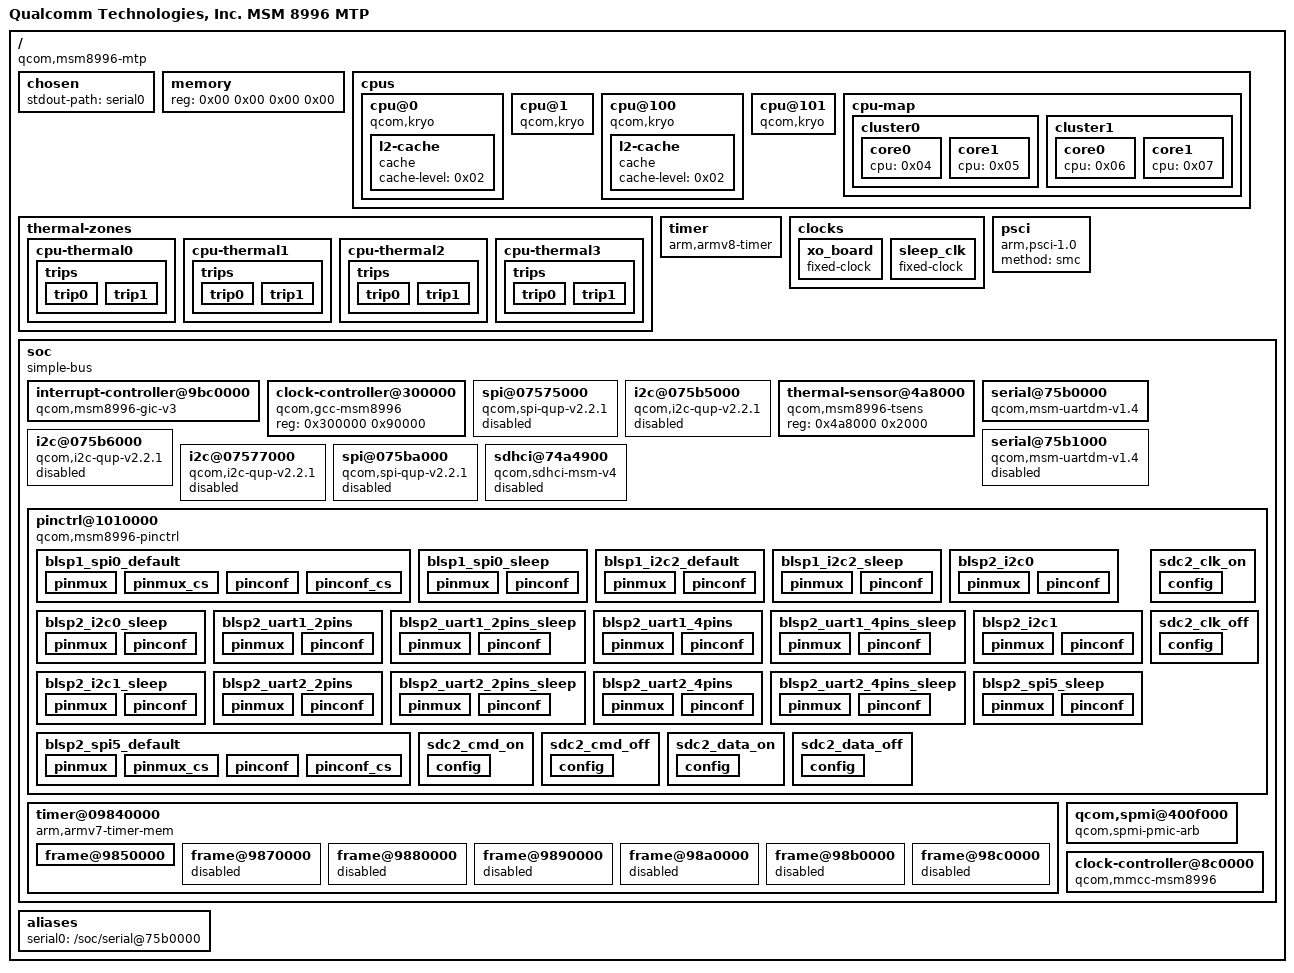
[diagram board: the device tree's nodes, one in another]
/dts-v1/;

/ {
	model = "Qualcomm Technologies, Inc. MSM 8996 MTP";
	interrupt-parent = <0x01>;
	#address-cells = <0x02>;
	#size-cells = <0x02>;
	compatible = "qcom,msm8996-mtp";

	chosen {
		stdout-path = "serial0";
	};

	memory {
		device_type = "memory";
		reg = <0x00 0x00 0x00 0x00>;
	};

	cpus {
		#address-cells = <0x02>;
		#size-cells = <0x00>;

		cpu@0 {
			device_type = "cpu";
			compatible = "qcom,kryo";
			reg = <0x00 0x00>;
			enable-method = "psci";
			next-level-cache = <0x02>;
			phandle = <0x04>;

			l2-cache {
				compatible = "cache";
				cache-level = <0x02>;
				phandle = <0x02>;
			};
		};

		cpu@1 {
			device_type = "cpu";
			compatible = "qcom,kryo";
			reg = <0x00 0x01>;
			enable-method = "psci";
			next-level-cache = <0x02>;
			phandle = <0x05>;
		};

		cpu@100 {
			device_type = "cpu";
			compatible = "qcom,kryo";
			reg = <0x00 0x100>;
			enable-method = "psci";
			next-level-cache = <0x03>;
			phandle = <0x06>;

			l2-cache {
				compatible = "cache";
				cache-level = <0x02>;
				phandle = <0x03>;
			};
		};

		cpu@101 {
			device_type = "cpu";
			compatible = "qcom,kryo";
			reg = <0x00 0x101>;
			enable-method = "psci";
			next-level-cache = <0x03>;
			phandle = <0x07>;
		};

		cpu-map {

			cluster0 {

				core0 {
					cpu = <0x04>;
				};

				core1 {
					cpu = <0x05>;
				};
			};

			cluster1 {

				core0 {
					cpu = <0x06>;
				};

				core1 {
					cpu = <0x07>;
				};
			};
		};
	};

	thermal-zones {

		cpu-thermal0 {
			polling-delay-passive = <0xfa>;
			polling-delay = <0x3e8>;
			thermal-sensors = <0x08 0x03>;

			trips {

				trip0 {
					temperature = <0x124f8>;
					hysteresis = <0x7d0>;
					type = "passive";
					phandle = <0x15>;
				};

				trip1 {
					temperature = <0x1adb0>;
					hysteresis = <0x7d0>;
					type = "critical";
					phandle = <0x16>;
				};
			};
		};

		cpu-thermal1 {
			polling-delay-passive = <0xfa>;
			polling-delay = <0x3e8>;
			thermal-sensors = <0x08 0x05>;

			trips {

				trip0 {
					temperature = <0x124f8>;
					hysteresis = <0x7d0>;
					type = "passive";
					phandle = <0x17>;
				};

				trip1 {
					temperature = <0x1adb0>;
					hysteresis = <0x7d0>;
					type = "critical";
					phandle = <0x18>;
				};
			};
		};

		cpu-thermal2 {
			polling-delay-passive = <0xfa>;
			polling-delay = <0x3e8>;
			thermal-sensors = <0x08 0x08>;

			trips {

				trip0 {
					temperature = <0x124f8>;
					hysteresis = <0x7d0>;
					type = "passive";
					phandle = <0x19>;
				};

				trip1 {
					temperature = <0x1adb0>;
					hysteresis = <0x7d0>;
					type = "critical";
					phandle = <0x1a>;
				};
			};
		};

		cpu-thermal3 {
			polling-delay-passive = <0xfa>;
			polling-delay = <0x3e8>;
			thermal-sensors = <0x08 0x0a>;

			trips {

				trip0 {
					temperature = <0x124f8>;
					hysteresis = <0x7d0>;
					type = "passive";
					phandle = <0x1b>;
				};

				trip1 {
					temperature = <0x1adb0>;
					hysteresis = <0x7d0>;
					type = "critical";
					phandle = <0x1c>;
				};
			};
		};
	};

	timer {
		compatible = "arm,armv8-timer";
		interrupts = <0x01 0x0d 0xf08 0x01 0x0e 0xf08 0x01 0x0b 0xf08 0x01 0x0a 0xf08>;
	};

	clocks {

		xo_board {
			compatible = "fixed-clock";
			#clock-cells = <0x00>;
			clock-frequency = <0x124f800>;
			clock-output-names = "xo_board";
		};

		sleep_clk {
			compatible = "fixed-clock";
			#clock-cells = <0x00>;
			clock-frequency = <0x7ffc>;
			clock-output-names = "sleep_clk";
		};
	};

	psci {
		compatible = "arm,psci-1.0";
		method = "smc";
	};

	soc {
		#address-cells = <0x01>;
		#size-cells = <0x01>;
		ranges = <0x00 0x00 0x00 0xffffffff>;
		compatible = "simple-bus";
		phandle = <0x1d>;

		interrupt-controller@9bc0000 {
			compatible = "qcom,msm8996-gic-v3\0arm,gic-v3";
			#interrupt-cells = <0x03>;
			interrupt-controller;
			#redistributor-regions = <0x01>;
			redistributor-stride = <0x00 0x40000>;
			reg = <0x9bc0000 0x10000 0x9c00000 0x100000>;
			interrupts = <0x01 0x09 0x04>;
			phandle = <0x01>;
		};

		clock-controller@300000 {
			compatible = "qcom,gcc-msm8996";
			#clock-cells = <0x01>;
			#reset-cells = <0x01>;
			#power-domain-cells = <0x01>;
			reg = <0x300000 0x90000>;
			phandle = <0x09>;
		};

		spi@07575000 {
			compatible = "qcom,spi-qup-v2.2.1";
			reg = <0x7575000 0x600>;
			interrupts = <0x00 0x5f 0x04>;
			clocks = <0x09 0x6f 0x09 0x6d>;
			clock-names = "core\0iface";
			pinctrl-names = "default\0sleep";
			pinctrl-0 = <0x0a>;
			pinctrl-1 = <0x0b>;
			#address-cells = <0x01>;
			#size-cells = <0x00>;
			status = "disabled";
			phandle = <0x1e>;
		};

		i2c@075b5000 {
			compatible = "qcom,i2c-qup-v2.2.1";
			reg = <0x75b5000 0x1000>;
			interrupts = <0x00 0x65 0x00>;
			clocks = <0x09 0x81 0x09 0x84>;
			clock-names = "iface\0core";
			pinctrl-names = "default\0sleep";
			pinctrl-0 = <0x0c>;
			pinctrl-1 = <0x0d>;
			#address-cells = <0x01>;
			#size-cells = <0x00>;
			status = "disabled";
			phandle = <0x1f>;
		};

		thermal-sensor@4a8000 {
			compatible = "qcom,msm8996-tsens";
			reg = <0x4a8000 0x2000>;
			#thermal-sensor-cells = <0x01>;
			phandle = <0x08>;
		};

		serial@75b0000 {
			compatible = "qcom,msm-uartdm-v1.4\0qcom,msm-uartdm";
			reg = <0x75b0000 0x1000>;
			interrupts = <0x00 0x72 0x04>;
			clocks = <0x09 0x88 0x09 0x81>;
			clock-names = "core\0iface";
			status = "okay";
			phandle = <0x20>;
		};

		i2c@075b6000 {
			compatible = "qcom,i2c-qup-v2.2.1";
			reg = <0x75b6000 0x1000>;
			interrupts = <0x00 0x66 0x00>;
			clocks = <0x09 0x81 0x09 0x87>;
			clock-names = "iface\0core";
			pinctrl-names = "default\0sleep";
			pinctrl-0 = <0x0e>;
			pinctrl-1 = <0x0f>;
			#address-cells = <0x01>;
			#size-cells = <0x00>;
			status = "disabled";
			phandle = <0x21>;
		};

		serial@75b1000 {
			compatible = "qcom,msm-uartdm-v1.4\0qcom,msm-uartdm";
			reg = <0x75b1000 0x1000>;
			interrupts = <0x00 0x73 0x04>;
			clocks = <0x09 0x8b 0x09 0x81>;
			clock-names = "core\0iface";
			status = "disabled";
			phandle = <0x22>;
		};

		i2c@07577000 {
			compatible = "qcom,i2c-qup-v2.2.1";
			reg = <0x7577000 0x1000>;
			interrupts = <0x00 0x61 0x00>;
			clocks = <0x09 0x6d 0x09 0x76>;
			clock-names = "iface\0core";
			pinctrl-names = "default\0sleep";
			pinctrl-0 = <0x10>;
			pinctrl-1 = <0x11>;
			#address-cells = <0x01>;
			#size-cells = <0x00>;
			status = "disabled";
			phandle = <0x23>;
		};

		spi@075ba000 {
			compatible = "qcom,spi-qup-v2.2.1";
			reg = <0x75ba000 0x600>;
			interrupts = <0x00 0x6a 0x04>;
			clocks = <0x09 0x92 0x09 0x81>;
			clock-names = "core\0iface";
			pinctrl-names = "default\0sleep";
			pinctrl-0 = <0x12>;
			pinctrl-1 = <0x13>;
			#address-cells = <0x01>;
			#size-cells = <0x00>;
			status = "disabled";
			phandle = <0x24>;
		};

		sdhci@74a4900 {
			status = "disabled";
			compatible = "qcom,sdhci-msm-v4";
			reg = <0x74a4900 0x314 0x74a4000 0x800>;
			reg-names = "hc_mem\0core_mem";
			interrupts = <0x00 0x7d 0x00 0x00 0xdd 0x00>;
			interrupt-names = "hc_irq\0pwr_irq";
			clock-names = "iface\0core";
			clocks = <0x09 0x68 0x09 0x67>;
			bus-width = <0x04>;
			phandle = <0x25>;
		};

		pinctrl@1010000 {
			compatible = "qcom,msm8996-pinctrl";
			reg = <0x1010000 0x300000>;
			interrupts = <0x00 0xd0 0x04>;
			gpio-controller;
			#gpio-cells = <0x02>;
			interrupt-controller;
			#interrupt-cells = <0x02>;
			phandle = <0x26>;

			blsp1_spi0_default {
				phandle = <0x0a>;

				pinmux {
					function = "blsp_spi1";
					pins = "gpio0\0gpio1\0gpio3";
				};

				pinmux_cs {
					function = "gpio";
					pins = "gpio2";
				};

				pinconf {
					pins = "gpio0\0gpio1\0gpio3";
					drive-strength = <0x0c>;
					bias-disable;
				};

				pinconf_cs {
					pins = "gpio2";
					drive-strength = <0x10>;
					bias-disable;
					output-high;
				};
			};

			blsp1_spi0_sleep {
				phandle = <0x0b>;

				pinmux {
					function = "gpio";
					pins = "gpio0\0gpio1\0gpio2\0gpio3";
				};

				pinconf {
					pins = "gpio0\0gpio1\0gpio2\0gpio3";
					drive-strength = <0x02>;
					bias-pull-down;
				};
			};

			blsp1_i2c2_default {
				phandle = <0x10>;

				pinmux {
					function = "blsp_i2c3";
					pins = "gpio47\0gpio48";
				};

				pinconf {
					pins = "gpio47\0gpio48";
					drive-strength = <0x10>;
					bias-disable = <0x00>;
				};
			};

			blsp1_i2c2_sleep {
				phandle = <0x11>;

				pinmux {
					function = "gpio";
					pins = "gpio47\0gpio48";
				};

				pinconf {
					pins = "gpio47\0gpio48";
					drive-strength = <0x02>;
					bias-disable = <0x00>;
				};
			};

			blsp2_i2c0 {
				phandle = <0x0c>;

				pinmux {
					function = "blsp_i2c7";
					pins = "gpio55\0gpio56";
				};

				pinconf {
					pins = "gpio55\0gpio56";
					drive-strength = <0x10>;
					bias-disable;
				};
			};

			blsp2_i2c0_sleep {
				phandle = <0x0d>;

				pinmux {
					function = "gpio";
					pins = "gpio55\0gpio56";
				};

				pinconf {
					pins = "gpio55\0gpio56";
					drive-strength = <0x02>;
					bias-disable;
				};
			};

			blsp2_uart1_2pins {
				phandle = <0x27>;

				pinmux {
					function = "blsp_uart8";
					pins = "gpio4\0gpio5";
				};

				pinconf {
					pins = "gpio4\0gpio5";
					drive-strength = <0x10>;
					bias-disable;
				};
			};

			blsp2_uart1_2pins_sleep {
				phandle = <0x28>;

				pinmux {
					function = "gpio";
					pins = "gpio4\0gpio5";
				};

				pinconf {
					pins = "gpio4\0gpio5";
					drive-strength = <0x02>;
					bias-disable;
				};
			};

			blsp2_uart1_4pins {
				phandle = <0x29>;

				pinmux {
					function = "blsp_uart8";
					pins = "gpio4\0gpio5\0gpio6\0gpio7";
				};

				pinconf {
					pins = "gpio4\0gpio5\0gpio6\0gpio7";
					drive-strength = <0x10>;
					bias-disable;
				};
			};

			blsp2_uart1_4pins_sleep {
				phandle = <0x2a>;

				pinmux {
					function = "gpio";
					pins = "gpio4\0gpio5\0gpio6\0gpio7";
				};

				pinconf {
					pins = "gpio4\0gpiio5\0gpio6\0gpio7";
					drive-strength = <0x02>;
					bias-disable;
				};
			};

			blsp2_i2c1 {
				phandle = <0x0e>;

				pinmux {
					function = "blsp_i2c8";
					pins = "gpio6\0gpio7";
				};

				pinconf {
					pins = "gpio6\0gpio7";
					drive-strength = <0x10>;
					bias-disable;
				};
			};

			blsp2_i2c1_sleep {
				phandle = <0x0f>;

				pinmux {
					function = "gpio";
					pins = "gpio6\0gpio7";
				};

				pinconf {
					pins = "gpio6\0gpio7";
					drive-strength = <0x02>;
					bias-disable;
				};
			};

			blsp2_uart2_2pins {
				phandle = <0x2b>;

				pinmux {
					function = "blsp_uart9";
					pins = "gpio49\0gpio50";
				};

				pinconf {
					pins = "gpio49\0gpio50";
					drive-strength = <0x10>;
					bias-disable;
				};
			};

			blsp2_uart2_2pins_sleep {
				phandle = <0x2c>;

				pinmux {
					function = "gpio";
					pins = "gpio49\0gpio50";
				};

				pinconf {
					pins = "gpio49\0gpio50";
					drive-strength = <0x02>;
					bias-disable;
				};
			};

			blsp2_uart2_4pins {
				phandle = <0x2d>;

				pinmux {
					function = "blsp_uart9";
					pins = "gpio49\0gpio50\0gpio51\0gpio52";
				};

				pinconf {
					pins = "gpio49\0gpio50\0gpio51\0gpio52";
					drive-strength = <0x10>;
					bias-disable;
				};
			};

			blsp2_uart2_4pins_sleep {
				phandle = <0x2e>;

				pinmux {
					function = "gpio";
					pins = "gpio49\0gpio50\0gpio51\0gpio52";
				};

				pinconf {
					pins = "gpio49\0gpio50\0gpio51\0gpio52";
					drive-strength = <0x02>;
					bias-disable;
				};
			};

			blsp2_spi5_default {
				phandle = <0x12>;

				pinmux {
					function = "blsp_spi12";
					pins = "gpio85\0gpio86\0gpio88";
				};

				pinmux_cs {
					function = "gpio";
					pins = "gpio87";
				};

				pinconf {
					pins = "gpio85\0gpio86\0gpio88";
					drive-strength = <0x0c>;
					bias-disable;
				};

				pinconf_cs {
					pins = "gpio87";
					drive-strength = <0x10>;
					bias-disable;
					output-high;
				};
			};

			blsp2_spi5_sleep {
				phandle = <0x13>;

				pinmux {
					function = "gpio";
					pins = "gpio85\0gpio86\0gpio87\0gpio88";
				};

				pinconf {
					pins = "gpio85\0gpio86\0gpio87\0gpio88";
					drive-strength = <0x02>;
					bias-pull-down;
				};
			};

			sdc2_clk_on {
				phandle = <0x2f>;

				config {
					pins = "sdc2_clk";
					bias-disable;
					drive-strength = <0x10>;
				};
			};

			sdc2_clk_off {
				phandle = <0x30>;

				config {
					pins = "sdc2_clk";
					bias-disable;
					drive-strength = <0x02>;
				};
			};

			sdc2_cmd_on {
				phandle = <0x31>;

				config {
					pins = "sdc2_cmd";
					bias-pull-up;
					drive-strength = <0x0a>;
				};
			};

			sdc2_cmd_off {
				phandle = <0x32>;

				config {
					pins = "sdc2_cmd";
					bias-pull-up;
					drive-strength = <0x02>;
				};
			};

			sdc2_data_on {
				phandle = <0x33>;

				config {
					pins = "sdc2_data";
					bias-pull-up;
					drive-strength = <0x0a>;
				};
			};

			sdc2_data_off {
				phandle = <0x34>;

				config {
					pins = "sdc2_data";
					bias-pull-up;
					drive-strength = <0x02>;
				};
			};
		};

		timer@09840000 {
			#address-cells = <0x01>;
			#size-cells = <0x01>;
			ranges;
			compatible = "arm,armv7-timer-mem";
			reg = <0x9840000 0x1000>;
			clock-frequency = <0x124f800>;

			frame@9850000 {
				frame-number = <0x00>;
				interrupts = <0x00 0x1f 0x04 0x00 0x1e 0x04>;
				reg = <0x9850000 0x1000 0x9860000 0x1000>;
			};

			frame@9870000 {
				frame-number = <0x01>;
				interrupts = <0x00 0x20 0x04>;
				reg = <0x9870000 0x1000>;
				status = "disabled";
			};

			frame@9880000 {
				frame-number = <0x02>;
				interrupts = <0x00 0x21 0x04>;
				reg = <0x9880000 0x1000>;
				status = "disabled";
			};

			frame@9890000 {
				frame-number = <0x03>;
				interrupts = <0x00 0x22 0x04>;
				reg = <0x9890000 0x1000>;
				status = "disabled";
			};

			frame@98a0000 {
				frame-number = <0x04>;
				interrupts = <0x00 0x23 0x04>;
				reg = <0x98a0000 0x1000>;
				status = "disabled";
			};

			frame@98b0000 {
				frame-number = <0x05>;
				interrupts = <0x00 0x24 0x04>;
				reg = <0x98b0000 0x1000>;
				status = "disabled";
			};

			frame@98c0000 {
				frame-number = <0x06>;
				interrupts = <0x00 0x25 0x04>;
				reg = <0x98c0000 0x1000>;
				status = "disabled";
			};
		};

		qcom,spmi@400f000 {
			compatible = "qcom,spmi-pmic-arb";
			reg = <0x400f000 0x1000 0x4400000 0x800000 0x4c00000 0x800000 0x5800000 0x200000 0x400a000 0x2100>;
			reg-names = "core\0chnls\0obsrvr\0intr\0cnfg";
			interrupt-names = "periph_irq";
			interrupts = <0x00 0x146 0x04>;
			qcom,ee = <0x00>;
			qcom,channel = <0x00>;
			#address-cells = <0x02>;
			#size-cells = <0x00>;
			interrupt-controller;
			#interrupt-cells = <0x04>;
			phandle = <0x35>;
		};

		clock-controller@8c0000 {
			compatible = "qcom,mmcc-msm8996";
			#clock-cells = <0x01>;
			#reset-cells = <0x01>;
			#power-domain-cells = <0x01>;
			reg = <0x8c0000 0x40000>;
			assigned-clocks = <0x14 0x0f 0x14 0x03 0x14 0x07 0x14 0x09 0x14 0x0b>;
			assigned-clock-rates = <0x25317c00 0x30479e80 0x3a699d00 0x39387000 0x312c8040>;
			phandle = <0x14>;
		};
	};

	aliases {
		serial0 = "/soc/serial@75b0000";
	};

	__symbols__ {
		CPU0 = "/cpus/cpu@0";
		L2_0 = "/cpus/cpu@0/l2-cache";
		CPU1 = "/cpus/cpu@1";
		CPU2 = "/cpus/cpu@100";
		L2_1 = "/cpus/cpu@100/l2-cache";
		CPU3 = "/cpus/cpu@101";
		cpu_alert0 = "/thermal-zones/cpu-thermal0/trips/trip0";
		cpu_crit0 = "/thermal-zones/cpu-thermal0/trips/trip1";
		cpu_alert1 = "/thermal-zones/cpu-thermal1/trips/trip0";
		cpu_crit1 = "/thermal-zones/cpu-thermal1/trips/trip1";
		cpu_alert2 = "/thermal-zones/cpu-thermal2/trips/trip0";
		cpu_crit2 = "/thermal-zones/cpu-thermal2/trips/trip1";
		cpu_alert3 = "/thermal-zones/cpu-thermal3/trips/trip0";
		cpu_crit3 = "/thermal-zones/cpu-thermal3/trips/trip1";
		soc = "/soc";
		intc = "/soc/interrupt-controller@9bc0000";
		gcc = "/soc/clock-controller@300000";
		blsp1_spi0 = "/soc/spi@07575000";
		blsp2_i2c0 = "/soc/i2c@075b5000";
		tsens0 = "/soc/thermal-sensor@4a8000";
		blsp2_uart1 = "/soc/serial@75b0000";
		blsp2_i2c1 = "/soc/i2c@075b6000";
		blsp2_uart2 = "/soc/serial@75b1000";
		blsp1_i2c2 = "/soc/i2c@07577000";
		blsp2_spi5 = "/soc/spi@075ba000";
		sdhc2 = "/soc/sdhci@74a4900";
		msmgpio = "/soc/pinctrl@1010000";
		blsp1_spi0_default = "/soc/pinctrl@1010000/blsp1_spi0_default";
		blsp1_spi0_sleep = "/soc/pinctrl@1010000/blsp1_spi0_sleep";
		blsp1_i2c2_default = "/soc/pinctrl@1010000/blsp1_i2c2_default";
		blsp1_i2c2_sleep = "/soc/pinctrl@1010000/blsp1_i2c2_sleep";
		blsp2_i2c0_default = "/soc/pinctrl@1010000/blsp2_i2c0";
		blsp2_i2c0_sleep = "/soc/pinctrl@1010000/blsp2_i2c0_sleep";
		blsp2_uart1_2pins_default = "/soc/pinctrl@1010000/blsp2_uart1_2pins";
		blsp2_uart1_2pins_sleep = "/soc/pinctrl@1010000/blsp2_uart1_2pins_sleep";
		blsp2_uart1_4pins_default = "/soc/pinctrl@1010000/blsp2_uart1_4pins";
		blsp2_uart1_4pins_sleep = "/soc/pinctrl@1010000/blsp2_uart1_4pins_sleep";
		blsp2_i2c1_default = "/soc/pinctrl@1010000/blsp2_i2c1";
		blsp2_i2c1_sleep = "/soc/pinctrl@1010000/blsp2_i2c1_sleep";
		blsp2_uart2_2pins_default = "/soc/pinctrl@1010000/blsp2_uart2_2pins";
		blsp2_uart2_2pins_sleep = "/soc/pinctrl@1010000/blsp2_uart2_2pins_sleep";
		blsp2_uart2_4pins_default = "/soc/pinctrl@1010000/blsp2_uart2_4pins";
		blsp2_uart2_4pins_sleep = "/soc/pinctrl@1010000/blsp2_uart2_4pins_sleep";
		blsp2_spi5_default = "/soc/pinctrl@1010000/blsp2_spi5_default";
		blsp2_spi5_sleep = "/soc/pinctrl@1010000/blsp2_spi5_sleep";
		sdc2_clk_on = "/soc/pinctrl@1010000/sdc2_clk_on";
		sdc2_clk_off = "/soc/pinctrl@1010000/sdc2_clk_off";
		sdc2_cmd_on = "/soc/pinctrl@1010000/sdc2_cmd_on";
		sdc2_cmd_off = "/soc/pinctrl@1010000/sdc2_cmd_off";
		sdc2_data_on = "/soc/pinctrl@1010000/sdc2_data_on";
		sdc2_data_off = "/soc/pinctrl@1010000/sdc2_data_off";
		spmi_bus = "/soc/qcom,spmi@400f000";
		mmcc = "/soc/clock-controller@8c0000";
	};
};
